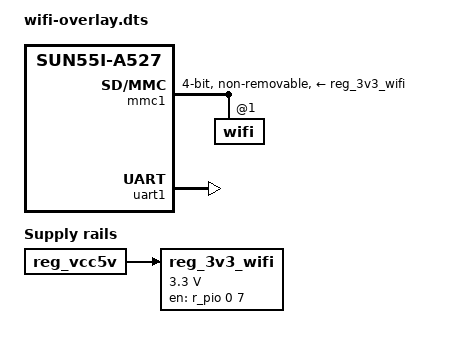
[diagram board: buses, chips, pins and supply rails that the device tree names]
/*
 * Vendored from https://github.com/patryk4815/nixos-cubie-a5e
 * (modules/wifi-overlay.dts)
 */
/dts-v1/;
/plugin/;

#include <dt-bindings/gpio/gpio.h>

/ {
	compatible = "radxa,cubie-a5e", "allwinner,sun55i-a527";

	/* WiFi 3.3V power via PL7 - from Armbian Cubie A5E DTS */
	fragment@0 {
		target-path = "/";
		__overlay__ {
			reg_3v3_wifi: 3v3-wifi {
				compatible = "regulator-fixed";
				regulator-name = "3v3-wifi";
				regulator-min-microvolt = <3300000>;
				regulator-max-microvolt = <3300000>;
				vin-supply = <&reg_vcc5v>;
				gpio = <&r_pio 0 7 GPIO_ACTIVE_HIGH>; /* PL7 */
				enable-active-high;
			};
		};
	};

	/* Increase mmc1 pin drive strength */
	fragment@1 {
		target = <&mmc1_pins>;
		__overlay__ {
			drive-strength = <40>;
		};
	};

	/* Enable mmc1 (SDIO1) for WiFi */
	fragment@2 {
		target = <&mmc1>;
		__overlay__ {
			vmmc-supply = <&reg_3v3_wifi>;
			bus-width = <4>;
			non-removable;
			max-frequency = <35000000>;
			status = "okay";

			wifi@1 {
				reg = <1>;
			};
		};
	};

	/* Enable UART1 for Bluetooth */
	fragment@3 {
		target = <&uart1>;
		__overlay__ {
			pinctrl-names = "default";
			pinctrl-0 = <&uart1_pins>, <&uart1_rts_cts_pins>;
			uart-has-rtscts;
			status = "okay";

			bluetooth {
				shutdown-gpios = <&r_pio 1 2 GPIO_ACTIVE_LOW>;
				host-wakeup-gpios = <&r_pio 1 4 GPIO_ACTIVE_HIGH>;
				device-wakeup-gpios = <&r_pio 1 3 GPIO_ACTIVE_HIGH>;
			};
		};
	};
};
